VERSION ""

NS_ :

BS_:

BU_: IRON_MD_TX IRON_MD_RX

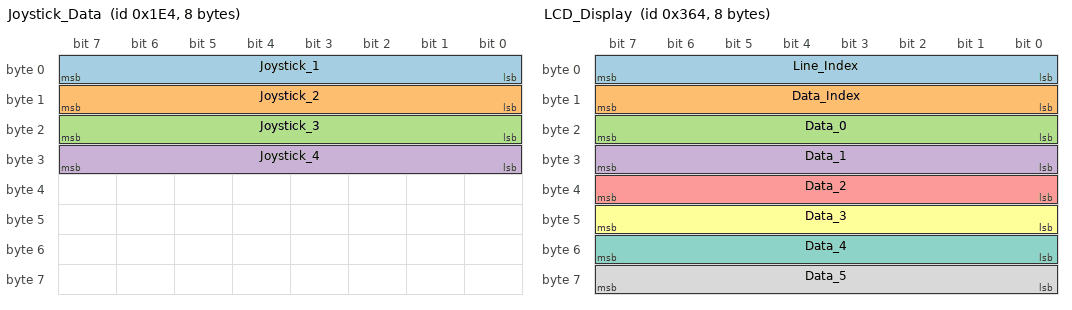
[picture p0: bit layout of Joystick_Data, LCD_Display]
BO_ 484 Joystick_Data: 8 IRON_MD_TX
 SG_ Joystick_1 : 0|8@1+ (1,0) [0|255] "" IRON_MD_RX
 SG_ Joystick_2 : 8|8@1+ (1,0) [0|255] "" IRON_MD_RX
 SG_ Joystick_3 : 16|8@1+ (1,0) [0|255] "" IRON_MD_RX
 SG_ Joystick_4 : 24|8@1+ (1,0) [0|255] "" IRON_MD_RX

BO_ 740 Switch_Status: 8 IRON_MD_TX
 SG_ Start_Key : 0|1@1+ (1,0) [0|1] "" IRON_MD_RX
 SG_ Power_Key : 1|1@1+ (1,0) [0|1] "" IRON_MD_RX
 SG_ Engine_Start : 2|1@1+ (1,0) [0|1] "" IRON_MD_RX
 SG_ Engine_Stop : 3|1@1+ (1,0) [0|1] "" IRON_MD_RX
 SG_ Emergency_Stop_Release : 6|1@1+ (1,0) [0|1] "" IRON_MD_RX
 SG_ Emergency_Stop_Active : 7|1@1+ (1,0) [0|1] "" IRON_MD_RX
 SG_ Switch_S00 : 15|1@1+ (1,0) [0|1] "" IRON_MD_RX
 SG_ Switch_S01 : 14|1@1+ (1,0) [0|1] "" IRON_MD_RX
 SG_ Switch_S02 : 12|1@1+ (1,0) [0|1] "" IRON_MD_RX
 SG_ Switch_S03 : 13|1@1+ (1,0) [0|1] "" IRON_MD_RX
 SG_ Switch_S06 : 8|1@1+ (1,0) [0|1] "" IRON_MD_RX
 SG_ Switch_S07 : 9|1@1+ (1,0) [0|1] "" IRON_MD_RX
 SG_ Switch_S08 : 16|1@1+ (1,0) [0|1] "" IRON_MD_RX
 SG_ Switch_S09 : 17|1@1+ (1,0) [0|1] "" IRON_MD_RX
 SG_ Switch_S17 : 30|1@1+ (1,0) [0|1] "" IRON_MD_RX
 SG_ Switch_S18 : 31|1@1+ (1,0) [0|1] "" IRON_MD_RX
 SG_ Switch_S19 : 28|1@1+ (1,0) [0|1] "" IRON_MD_RX
 SG_ Switch_S20 : 29|1@1+ (1,0) [0|1] "" IRON_MD_RX
 SG_ Switch_S21 : 26|1@1+ (1,0) [0|1] "" IRON_MD_RX
 SG_ Switch_S22 : 27|1@1+ (1,0) [0|1] "" IRON_MD_RX
 SG_ Switch_S23 : 24|1@1+ (1,0) [0|1] "" IRON_MD_RX
 SG_ Switch_S24 : 25|1@1+ (1,0) [0|1] "" IRON_MD_RX
 SG_ Run_Counter : 32|4@1+ (1,0) [0|15] "" IRON_MD_RX
 SG_ Cal_Mode : 36|1@1+ (1,0) [0|1] "" IRON_MD_RX
 SG_ TX_Connected : 54|1@1+ (1,0) [0|1] "" IRON_MD_RX
 SG_ TRX_Code : 55|1@1+ (1,0) [0|1] "" IRON_MD_RX
 SG_ Serial_Number : 56|8@1+ (1,0) [0|255] "" IRON_MD_RX
 SG_ Device_ID : 64|8@1+ (1,0) [0|255] "" IRON_MD_RX

BO_ 1892 Heartbeat: 8 IRON_MD_TX
 SG_ Heart_Bit : 0|8@1+ (1,0) [0|0] "" IRON_MD_RX

BO_ 868 LCD_Display: 8 IRON_MD_RX
 SG_ Line_Index : 0|8@1+ (1,0) [0|15] "" IRON_MD_TX
 SG_ Data_Index : 8|8@1+ (1,0) [0|10] "" IRON_MD_TX
 SG_ Data_0 : 16|8@1+ (1,0) [0|255] "" IRON_MD_TX
 SG_ Data_1 : 24|8@1+ (1,0) [0|255] "" IRON_MD_TX
 SG_ Data_2 : 32|8@1+ (1,0) [0|255] "" IRON_MD_TX
 SG_ Data_3 : 40|8@1+ (1,0) [0|255] "" IRON_MD_TX
 SG_ Data_4 : 48|8@1+ (1,0) [0|255] "" IRON_MD_TX
 SG_ Data_5 : 56|8@1+ (1,0) [0|255] "" IRON_MD_TX

CM_ BO_ 484 "Joystick analog data - TX every 50ms";
CM_ SG_ 484 Joystick_1 "Joystick 1 analog value (0-255)";
CM_ SG_ 484 Joystick_2 "Joystick 2 analog value (0-255)";
CM_ SG_ 484 Joystick_3 "Joystick 3 analog value (0-255)";
CM_ SG_ 484 Joystick_4 "Joystick 4 analog value (0-255)";

CM_ BO_ 740 "Digital switches and status - TX every 50ms";
CM_ SG_ 740 Start_Key "Start key button";
CM_ SG_ 740 Power_Key "Power on key button";
CM_ SG_ 740 Engine_Start "Engine start switch (S13)";
CM_ SG_ 740 Engine_Stop "Engine stop switch (S14)";
CM_ SG_ 740 Emergency_Stop_Release "Emergency stop: 0=Stop, 1=Release";
CM_ SG_ 740 Emergency_Stop_Active "Emergency stop: 1=Stop, 0=Release";
CM_ SG_ 740 Run_Counter "Received signal counter (0-16)";
CM_ SG_ 740 Cal_Mode "Calibration mode: 1=Cal mode, 0=Normal mode";
CM_ SG_ 740 TX_Connected "Transmitter connection status: 1=Connected";
CM_ SG_ 740 TRX_Code "Device type: 1=Transmitter, 0=Receiver";
CM_ SG_ 740 Serial_Number "Device serial number (reference)";
CM_ SG_ 740 Device_ID "Device ID number (reference)";

CM_ BO_ 1892 "Heartbeat signal - TX every 300ms";
CM_ SG_ 1892 Heart_Bit "Heartbeat, always outputs 0";

CM_ BO_ 868 "LCD display data - RX >100ms (Optional, not used)";
CM_ SG_ 868 Line_Index "LCD line number (0-15, ignore >=12)";
CM_ SG_ 868 Data_Index "LCD character position (0-10, ignore >=8)";

BA_DEF_ "BusType" STRING ;
BA_DEF_ BO_  "GenMsgCycleTime" INT 0 10000;

BA_DEF_DEF_  "BusType" "CAN";
BA_DEF_DEF_  "GenMsgCycleTime" 0;

BA_ "GenMsgCycleTime" BO_ 484 50;
BA_ "GenMsgCycleTime" BO_ 740 50;
BA_ "GenMsgCycleTime" BO_ 1892 300;
BA_ "GenMsgCycleTime" BO_ 868 100;

VAL_ 740 Emergency_Stop_Release 0 "Emergency_Stop" 1 "Release" ;
VAL_ 740 Emergency_Stop_Active 1 "Emergency_Stop" 0 "Release" ;
VAL_ 740 Cal_Mode 0 "Normal_Mode" 1 "Calibration_Mode" ;
VAL_ 740 TX_Connected 0 "Disconnected" 1 "Connected" ;
VAL_ 740 TRX_Code 0 "Receiver" 1 "Transmitter" ;
